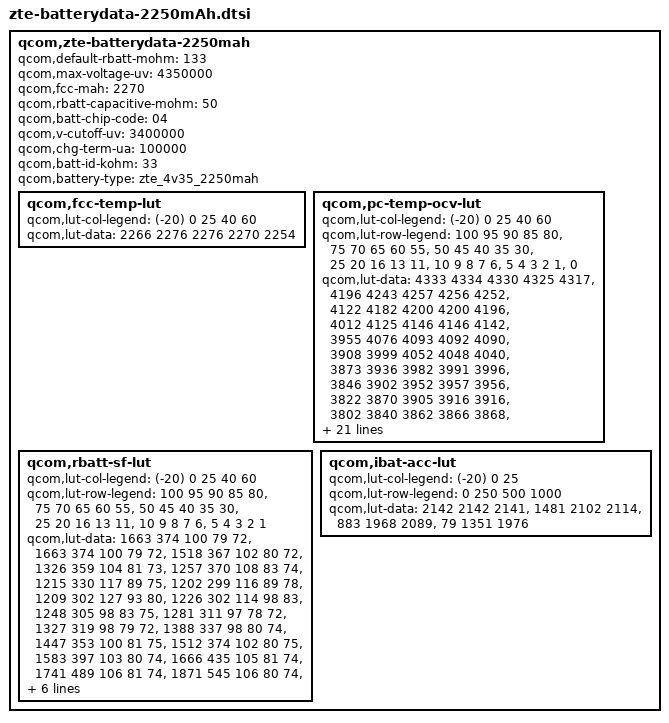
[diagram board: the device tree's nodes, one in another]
/* Copyright (c) 2014, The Linux Foundation. All rights reserved.
 *
 * This program is free software; you can redistribute it and/or modify
 * it under the terms of the GNU General Public License version 2 and
 * only version 2 as published by the Free Software Foundation.
 *
 * This program is distributed in the hope that it will be useful,
 * but WITHOUT ANY WARRANTY; without even the implied warranty of
 * MERCHANTABILITY or FITNESS FOR A PARTICULAR PURPOSE.  See the
 * GNU General Public License for more details.
 */

qcom,zte-batterydata-2250mah {
	qcom,default-rbatt-mohm = <133>;
	qcom,max-voltage-uv = <4350000>;
	qcom,fcc-mah = <2270>;
	qcom,rbatt-capacitive-mohm = <50>;
	qcom,batt-chip-code = <04>;
	qcom,v-cutoff-uv = <3400000>;
	qcom,chg-term-ua = <100000>;
	qcom,batt-id-kohm = <33>;
	qcom,battery-type = "zte_4v35_2250mah";

	qcom,fcc-temp-lut {
		qcom,lut-col-legend = <(-20) 0 25 40 60>;
		qcom,lut-data = <2266 2276 2276 2270 2254>;
	};

	qcom,pc-temp-ocv-lut {
		qcom,lut-col-legend = <(-20) 0 25 40 60>;
		qcom,lut-row-legend = <100 95 90 85 80>,
					<75 70 65 60 55>,
					<50 45 40 35 30>,
					<25 20 16 13 11>,
					<10 9 8 7 6>,
					<5 4 3 2 1>,
					<0>;
		qcom,lut-data = <4333 4334 4330 4325 4317>,
				<4196 4243 4257 4256 4252>,
				<4122 4182 4200 4200 4196>,
				<4012 4125 4146 4146 4142>,
				<3955 4076 4093 4092 4090>,
				<3908 3999 4052 4048 4040>,
				<3873 3936 3982 3991 3996>,
				<3846 3902 3952 3957 3956>,
				<3822 3870 3905 3916 3916>,
				<3802 3840 3862 3866 3868>,
				<3782 3816 3834 3836 3836>,
				<3762 3795 3812 3813 3812>,
				<3745 3779 3793 3794 3794>,
				<3726 3764 3778 3778 3778>,
				<3706 3748 3767 3764 3760>,
				<3688 3730 3756 3750 3738>,
				<3667 3716 3739 3732 3718>,
				<3646 3707 3714 3707 3693>,
				<3628 3700 3693 3686 3673>,
				<3613 3692 3688 3680 3668>,
				<3604 3688 3686 3680 3668>,
				<3594 3682 3685 3678 3666>,
				<3584 3674 3684 3677 3666>,
				<3571 3664 3680 3674 3662>,
				<3552 3648 3674 3668 3652>,
				<3531 3626 3653 3643 3622>,
				<3504 3592 3608 3597 3574>,
				<3468 3542 3546 3534 3510>,
				<3413 3465 3458 3447 3422>,
				<3317 3333 3320 3310 3284>,
				<3000 3000 3000 3000 3000>;
	};

	qcom,rbatt-sf-lut {
		qcom,lut-col-legend = <(-20) 0 25 40 60>;
		qcom,lut-row-legend = <100 95 90 85 80>,
					<75 70 65 60 55>,
					<50 45 40 35 30>,
					<25 20 16 13 11>,
					<10 9 8 7 6>,
					<5 4 3 2 1>;
		qcom,lut-data = <1663 374 100 79 72>,
				<1663 374 100 79 72>,
				<1518 367 102 80 72>,
				<1326 359 104 81 73>,
				<1257 370 108 83 74>,
				<1215 330 117 89 75>,
				<1202 299 116 89 78>,
				<1209 302 127 93 80>,
				<1226 302 114 98 83>,
				<1248 305 98 83 75>,
				<1281 311 97 78 72>,
				<1327 319 98 79 72>,
				<1388 337 98 80 74>,
				<1447 353 100 81 75>,
				<1512 374 102 80 75>,
				<1583 397 103 80 74>,
				<1666 435 105 81 74>,
				<1741 489 106 81 74>,
				<1871 545 106 80 74>,
				<1944 573 109 82 74>,
				<1983 586 111 83 74>,
				<2017 598 114 85 75>,
				<2202 625 118 87 76>,
				<2409 654 122 89 77>,
				<2675 686 129 89 76>,
				<3053 726 129 87 74>,
				<3535 771 128 86 76>,
				<4226 831 134 89 77>,
				<5353 905 144 94 80>,
				<7777 1147 185 141 123>;
	};

	qcom,ibat-acc-lut {
		qcom,lut-col-legend = <(-20) 0 25>;
		qcom,lut-row-legend = <0 250 500 1000>;
		qcom,lut-data = <2142 2142 2141>,
				<1481 2102 2114>,
				<883 1968 2089>,
				<79 1351 1976>;
	};
};
